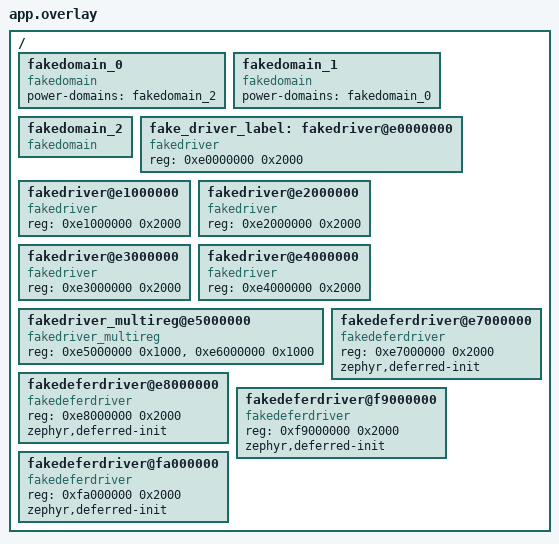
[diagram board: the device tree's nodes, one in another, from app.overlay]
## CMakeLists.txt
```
# SPDX-License-Identifier: Apache-2.0

cmake_minimum_required(VERSION 3.28.0)
find_package(Zephyr REQUIRED HINTS $ENV{ZEPHYR_BASE})
project(device)

FILE(GLOB app_sources src/*.c)
target_sources(app PRIVATE ${app_sources})

# device_get_binding() compares pointers first before doing strcmp().
# However, enabling coverage forces -O0 to disable any compiler
# optimizations. There would be multiple copies of the same string,
# and the code pathing doing pointer comparison would not be tested
# at all. So add this flag to merge string constants such that
# the pointer comparison would be exercised.
zephyr_cc_option_ifdef(CONFIG_COVERAGE -fmerge-constants)
```

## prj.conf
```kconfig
CONFIG_ZTEST=y
CONFIG_TEST_USERSPACE=y
CONFIG_PM_DEVICE=y
CONFIG_PM_DEVICE_RUNTIME=y
CONFIG_APPLICATION_DEFINED_SYSCALL=y
CONFIG_DEVICE_DEINIT_SUPPORT=y
```

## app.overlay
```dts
/*
 * Copyright (c) 2020 Nordic Semiconductor ASA
 * Copyright (c) 2020 Intel Corporation
 *
 * SPDX-License-Identifier: Apache-2.0
 *
 * Application overlay for creating a fake device instance we
 * can use to test DEVICE_MMIO APIs, which get raw data about
 * memory ranges from DTS instances.
 *
 * Names in this file should be chosen in a way that won't conflict
 * with real-world devicetree nodes, to allow these tests to run on
 * (and be extended to test) real hardware.
 */

/ {
	#address-cells = <1>;
	#size-cells = <1>;

	fakedomain_0: fakedomain_0 {
		compatible = "fakedomain";
		power-domains = <&fakedomain_2>;
		#power-domain-cells = <0>;
		status = "okay";
	};

	fakedomain_1: fakedomain_1 {
		compatible = "fakedomain";
		power-domains = <&fakedomain_0>;
		#power-domain-cells = <0>;
		status = "okay";
	};

	fakedomain_2: fakedomain_2 {
		compatible = "fakedomain";
		#power-domain-cells = <0>;
		status = "okay";
	};

	fake_driver_label: fakedriver@e0000000 {
		compatible = "fakedriver";
		reg = <0xe0000000 0x2000>;
		status = "okay";
	};

	fakedriver@e1000000 {
		compatible = "fakedriver";
		reg = <0xe1000000 0x2000>;
		status = "okay";
	};

	fakedriver@e2000000 {
		compatible = "fakedriver";
		reg = <0xe2000000 0x2000>;
		status = "okay";
	};

	fakedriver@e3000000 {
		compatible = "fakedriver";
		reg = <0xe3000000 0x2000>;
		status = "okay";
	};

	fakedriver@e4000000 {
		compatible = "fakedriver";
		reg = <0xe4000000 0x2000>;
		status = "okay";
	};

	fakedriver_multireg@e5000000 {
		compatible = "fakedriver_multireg";
		reg = <0xe5000000 0x1000>,
		      <0xe6000000 0x1000>;
		reg-names = "chip",
			    "dale";
		status = "okay";
	};

	fakedeferdriver@e7000000 {
		compatible = "fakedeferdriver";
		reg = <0xe7000000 0x2000>;
		zephyr,deferred-init;
		status = "okay";
	};

	fakedeferdriver@e8000000 {
		compatible = "fakedeferdriver";
		reg = <0xe8000000 0x2000>;
		zephyr,deferred-init;
		status = "okay";
	};

	fakedeferdriver@f9000000 {
		compatible = "fakedeferdriver";
		reg = <0xf9000000 0x2000>;
		zephyr,deferred-init;
		status = "okay";
	};

	fakedeferdriver@fa000000 {
		compatible = "fakedeferdriver";
		reg = <0xfa000000 0x2000>;
		zephyr,deferred-init;
		status = "okay";
	};
};
```

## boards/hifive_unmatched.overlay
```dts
/*
 * Copyright (c) 2020 Nordic Semiconductor ASA
 * Copyright (c) 2020 Intel Corporation
 *
 * SPDX-License-Identifier: Apache-2.0
 *
 * Application overlay for creating a fake device instance we
 * can use to test DEVICE_MMIO APIs, which get raw data about
 * memory ranges from DTS instances.
 *
 * Names in this file should be chosen in a way that won't conflict
 * with real-world devicetree nodes, to allow these tests to run on
 * (and be extended to test) real hardware.
 */

/ {
	fakedriver@E0000000 {
		compatible = "fakedriver";
		reg = <0x0 0xE0000000 0x0 0x2000>;
		status = "okay";
	};
	fakedriver@E1000000 {
		compatible = "fakedriver";
		reg = <0x0 0xE1000000 0x0 0x2000>;
		status = "okay";
	};
	fakedriver@E2000000 {
		compatible = "fakedriver";
		reg = <0x0 0xE2000000 0x0 0x2000>;
		status = "okay";
	};
	fakedriver@E3000000 {
		compatible = "fakedriver";
		reg = <0x0 0xE3000000 0x0 0x2000>;
		status = "okay";
	};
	fakedriver@E4000000 {
		compatible = "fakedriver";
		reg = <0x0 0xE4000000 0x0 0x2000>;
		status = "okay";
	};

	fakedriver_multireg@E5000000 {
		compatible = "fakedriver_multireg";
		reg = <0x0 0xE5000000 0x0 0x1000>,
		      <0x0 0xE6000000 0x0 0x1000>;
		reg-names = "chip",
			    "dale";
		status = "okay";
	};

	fakedeferdriver@E7000000 {
		compatible = "fakedeferdriver";
		reg = <0x0 0xE7000000 0x0 0x2000>;
		status = "okay";
		zephyr,deferred-init;
	};

	fakedeferdriver@E8000000 {
		compatible = "fakedeferdriver";
		reg = <0x0 0xE8000000 0x0 0x2000>;
		status = "okay";
		zephyr,deferred-init;
	};

	fakedomain_0: fakedomain_0 {
		compatible = "fakedomain";
		status = "okay";
		#power-domain-cells = <0>;
		power-domains = <&fakedomain_2>;
	};

	fakedomain_1: fakedomain_1 {
		compatible = "fakedomain";
		status = "okay";
		#power-domain-cells = <0>;
		power-domains = <&fakedomain_0>;
	};

	fakedomain_2: fakedomain_2 {
		compatible = "fakedomain";
		status = "okay";
		#power-domain-cells = <0>;
	};
};
```

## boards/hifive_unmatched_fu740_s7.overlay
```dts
/*
 * Copyright (c) 2020 Nordic Semiconductor ASA
 * Copyright (c) 2020 Intel Corporation
 *
 * SPDX-License-Identifier: Apache-2.0
 *
 * Application overlay for creating a fake device instance we
 * can use to test DEVICE_MMIO APIs, which get raw data about
 * memory ranges from DTS instances.
 *
 * Names in this file should be chosen in a way that won't conflict
 * with real-world devicetree nodes, to allow these tests to run on
 * (and be extended to test) real hardware.
 */

/ {
	fakedriver@e0000000 {
		compatible = "fakedriver";
		reg = <0x0 0xe0000000 0x0 0x2000>;
		status = "okay";
	};

	fakedriver@e1000000 {
		compatible = "fakedriver";
		reg = <0x0 0xe1000000 0x0 0x2000>;
		status = "okay";
	};

	fakedriver@e2000000 {
		compatible = "fakedriver";
		reg = <0x0 0xe2000000 0x0 0x2000>;
		status = "okay";
	};

	fakedriver@e3000000 {
		compatible = "fakedriver";
		reg = <0x0 0xe3000000 0x0 0x2000>;
		status = "okay";
	};

	fakedriver@e4000000 {
		compatible = "fakedriver";
		reg = <0x0 0xe4000000 0x0 0x2000>;
		status = "okay";
	};

	fakedriver_multireg@e5000000 {
		compatible = "fakedriver_multireg";
		reg = <0x0 0xe5000000 0x0 0x1000>,
		      <0x0 0xe6000000 0x0 0x1000>;
		reg-names = "chip",
			    "dale";
		status = "okay";
	};

	fakedeferdriver@e7000000 {
		compatible = "fakedeferdriver";
		reg = <0x0 0xe7000000 0x0 0x2000>;
		status = "okay";
		zephyr,deferred-init;
	};

	fakedeferdriver@e8000000 {
		compatible = "fakedeferdriver";
		reg = <0x0 0xe8000000 0x0 0x2000>;
		status = "okay";
		zephyr,deferred-init;
	};

	fakedeferdriver@f9000000 {
		compatible = "fakedeferdriver";
		reg = <0x0 0xf9000000 0x0 0x2000>;
		status = "okay";
		zephyr,deferred-init;
	};

	fakedeferdriver@fa000000 {
		compatible = "fakedeferdriver";
		reg = <0x0 0xfa000000 0x0 0x2000>;
		status = "okay";
		zephyr,deferred-init;
	};

	fakedomain_0: fakedomain_0 {
		compatible = "fakedomain";
		status = "okay";
		#power-domain-cells = <0>;
		power-domains = <&fakedomain_2>;
	};

	fakedomain_1: fakedomain_1 {
		compatible = "fakedomain";
		status = "okay";
		#power-domain-cells = <0>;
		power-domains = <&fakedomain_0>;
	};

	fakedomain_2: fakedomain_2 {
		compatible = "fakedomain";
		status = "okay";
		#power-domain-cells = <0>;
	};
};
```

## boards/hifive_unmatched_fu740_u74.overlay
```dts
/*
 * Copyright (c) 2020 Nordic Semiconductor ASA
 * Copyright (c) 2020 Intel Corporation
 *
 * SPDX-License-Identifier: Apache-2.0
 *
 * Application overlay for creating a fake device instance we
 * can use to test DEVICE_MMIO APIs, which get raw data about
 * memory ranges from DTS instances.
 *
 * Names in this file should be chosen in a way that won't conflict
 * with real-world devicetree nodes, to allow these tests to run on
 * (and be extended to test) real hardware.
 */

/ {
	fakedriver@e0000000 {
		compatible = "fakedriver";
		reg = <0x0 0xe0000000 0x0 0x2000>;
		status = "okay";
	};

	fakedriver@e1000000 {
		compatible = "fakedriver";
		reg = <0x0 0xe1000000 0x0 0x2000>;
		status = "okay";
	};

	fakedriver@e2000000 {
		compatible = "fakedriver";
		reg = <0x0 0xe2000000 0x0 0x2000>;
		status = "okay";
	};

	fakedriver@e3000000 {
		compatible = "fakedriver";
		reg = <0x0 0xe3000000 0x0 0x2000>;
		status = "okay";
	};

	fakedriver@e4000000 {
		compatible = "fakedriver";
		reg = <0x0 0xe4000000 0x0 0x2000>;
		status = "okay";
	};

	fakedriver_multireg@e5000000 {
		compatible = "fakedriver_multireg";
		reg = <0x0 0xe5000000 0x0 0x1000>,
		      <0x0 0xe6000000 0x0 0x1000>;
		reg-names = "chip",
			    "dale";
		status = "okay";
	};

	fakedeferdriver@e7000000 {
		compatible = "fakedeferdriver";
		reg = <0x0 0xe7000000 0x0 0x2000>;
		zephyr,deferred-init;
		status = "okay";
	};

	fakedeferdriver@e8000000 {
		compatible = "fakedeferdriver";
		reg = <0x0 0xe8000000 0x0 0x2000>;
		zephyr,deferred-init;
		status = "okay";
	};

	fakedeferdriver@f9000000 {
		compatible = "fakedeferdriver";
		reg = <0x0 0xf9000000 0x0 0x2000>;
		zephyr,deferred-init;
		status = "okay";
	};

	fakedeferdriver@fa000000 {
		compatible = "fakedeferdriver";
		reg = <0x0 0xfa000000 0x0 0x2000>;
		zephyr,deferred-init;
		status = "okay";
	};

	fakedomain_0: fakedomain_0 {
		compatible = "fakedomain";
		#power-domain-cells = <0>;
		power-domains = <&fakedomain_2>;
		status = "okay";
	};

	fakedomain_1: fakedomain_1 {
		compatible = "fakedomain";
		#power-domain-cells = <0>;
		power-domains = <&fakedomain_0>;
		status = "okay";
	};

	fakedomain_2: fakedomain_2 {
		compatible = "fakedomain";
		#power-domain-cells = <0>;
		status = "okay";
	};
};
```

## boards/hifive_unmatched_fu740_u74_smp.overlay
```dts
/*
 * Copyright (c) 2020 Nordic Semiconductor ASA
 * Copyright (c) 2020 Intel Corporation
 *
 * SPDX-License-Identifier: Apache-2.0
 *
 * Application overlay for creating a fake device instance we
 * can use to test DEVICE_MMIO APIs, which get raw data about
 * memory ranges from DTS instances.
 *
 * Names in this file should be chosen in a way that won't conflict
 * with real-world devicetree nodes, to allow these tests to run on
 * (and be extended to test) real hardware.
 */

/ {
	#address-cells = <2>;
	#size-cells = <2>;

	fakedriver@E0000000 {
		compatible = "fakedriver";
		reg = <0x0 0xE0000000 0x0 0x2000>;
		status = "okay";
	};
	fakedriver@E1000000 {
		compatible = "fakedriver";
		reg = <0x0 0xE1000000 0x0 0x2000>;
		status = "okay";
	};
	fakedriver@E2000000 {
		compatible = "fakedriver";
		reg = <0x0 0xE2000000 0x0 0x2000>;
		status = "okay";
	};
	fakedriver@E3000000 {
		compatible = "fakedriver";
		reg = <0x0 0xE3000000 0x0 0x2000>;
		status = "okay";
	};
	fakedriver@E4000000 {
		compatible = "fakedriver";
		reg = <0x0 0xE4000000 0x0 0x2000>;
		status = "okay";
	};

	fakedriver_multireg@E5000000 {
		compatible = "fakedriver_multireg";
		reg = <0x0 0xE5000000 0x0 0x1000>,
		      <0x0 0xE6000000 0x0 0x1000>;
		reg-names = "chip",
			    "dale";
		status = "okay";
	};

	fakedeferdriver@E7000000 {
		compatible = "fakedeferdriver";
		reg = <0x0 0xE7000000 0x0 0x2000>;
		status = "okay";
		zephyr,deferred-init;
	};

	fakedeferdriver@E8000000 {
		compatible = "fakedeferdriver";
		reg = <0x0 0xE8000000 0x0 0x2000>;
		status = "okay";
		zephyr,deferred-init;
	};

	fakedomain_0: fakedomain_0 {
		compatible = "fakedomain";
		status = "okay";
		power-domain = <&fakedomain_2>;
	};

	fakedomain_1: fakedomain_1 {
		compatible = "fakedomain";
		status = "okay";
		power-domain = <&fakedomain_0>;
	};

	fakedomain_2: fakedomain_2 {
		compatible = "fakedomain";
		status = "okay";
	};
};
```

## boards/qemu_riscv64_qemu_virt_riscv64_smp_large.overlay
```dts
/*
 * Copyright (c) 2020 Nordic Semiconductor ASA
 * Copyright (c) 2020 Intel Corporation
 * Copyright (c) Qualcomm Technologies, Inc. and/or its subsidiaries.
 *
 * SPDX-License-Identifier: Apache-2.0
 *
 * Board-specific overlay for qemu_riscv64/qemu_virt_riscv64/smp_large.
 * This board uses #address-cells = <2> at root, so fake device reg values
 * must use two address cells.  The root #address-cells is NOT overridden
 * here (unlike app.overlay) to avoid breaking the ram0 node at 0x100000000.
 */

/ {
	fake_driver_label: fakedriver@e0000000 {
		compatible = "fakedriver";
		reg = <0x0 0xe0000000 0x0 0x2000>;
		status = "okay";
	};

	fakedriver@e1000000 {
		compatible = "fakedriver";
		reg = <0x0 0xe1000000 0x0 0x2000>;
		status = "okay";
	};

	fakedriver@e2000000 {
		compatible = "fakedriver";
		reg = <0x0 0xe2000000 0x0 0x2000>;
		status = "okay";
	};

	fakedriver@e3000000 {
		compatible = "fakedriver";
		reg = <0x0 0xe3000000 0x0 0x2000>;
		status = "okay";
	};

	fakedriver@e4000000 {
		compatible = "fakedriver";
		reg = <0x0 0xe4000000 0x0 0x2000>;
		status = "okay";
	};

	fakedriver_multireg@e5000000 {
		compatible = "fakedriver_multireg";
		reg = <0x0 0xe5000000 0x0 0x1000>,
		      <0x0 0xe6000000 0x0 0x1000>;
		reg-names = "chip",
			    "dale";
		status = "okay";
	};

	fakedeferdriver@e7000000 {
		compatible = "fakedeferdriver";
		reg = <0x0 0xe7000000 0x0 0x2000>;
		status = "okay";
		zephyr,deferred-init;
	};

	fakedeferdriver@e8000000 {
		compatible = "fakedeferdriver";
		reg = <0x0 0xe8000000 0x0 0x2000>;
		status = "okay";
		zephyr,deferred-init;
	};

	fakedeferdriver@f9000000 {
		compatible = "fakedeferdriver";
		reg = <0x0 0xf9000000 0x0 0x2000>;
		status = "okay";
		zephyr,deferred-init;
	};

	fakedomain_0: fakedomain_0 {
		compatible = "fakedomain";
		status = "okay";
		#power-domain-cells = <0>;
		power-domains = <&fakedomain_2>;
	};

	fakedomain_1: fakedomain_1 {
		compatible = "fakedomain";
		status = "okay";
		#power-domain-cells = <0>;
		power-domains = <&fakedomain_0>;
	};

	fakedomain_2: fakedomain_2 {
		compatible = "fakedomain";
		status = "okay";
		#power-domain-cells = <0>;
	};
};
```

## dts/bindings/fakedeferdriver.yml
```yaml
# Copyright (c) 2023 Intel Corporation
# SPDX-License-Identifier: Apache-2.0

description: Properties for fake deferred driver.

compatible: "fakedeferdriver"

include: base.yaml
```

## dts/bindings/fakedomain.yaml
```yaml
# Copyright (c) 2023, CSIRO
# SPDX-License-Identifier: Apache-2.0

description: Properties for fake power domain

compatible: "fakedomain"

include: base.yaml
```

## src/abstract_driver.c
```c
/*
 * Copyright (c) 2020 Intel Corporation
 *
 * SPDX-License-Identifier: Apache-2.0
 */

#include <zephyr/ztest.h>
#include <zephyr/device.h>
#include "abstract_driver.h"

#define MY_DRIVER_A		"my_driver_A"
#define MY_DRIVER_B		"my_driver_B"
#define MY_CHILD_DRIVER		"my_child_driver"
#define MY_GRANDCHILD_DRIVER	"my_grandchild_driver"
#define MY_SIBLING_DRIVER	"my_sibling_driver"

/* define individual driver A */
static int my_driver_A_do_this(const struct device *dev, int foo, int bar)
{
	return foo + bar;
}

static void my_driver_A_do_that(const struct device *dev, unsigned int *baz)
{
	*baz = 1;
}

static DEVICE_API(abstract, my_driver_A_api_funcs) = {
	.do_this = my_driver_A_do_this,
	.do_that = my_driver_A_do_that,
};

int common_driver_init(const struct device *dev)
{
	return 0;
}

/* define individual driver B */
static int my_driver_B_do_this(const struct device *dev, int foo, int bar)
{
	return foo - bar;
}

static void my_driver_B_do_that(const struct device *dev, unsigned int *baz)
{
	*baz = 2;
}

static DEVICE_API(abstract, my_driver_B_api_funcs) = {
	.do_this = my_driver_B_do_this,
	.do_that = my_driver_B_do_that,
};

/* define child driver */
static int child_driver_do_this(const struct device *dev, int foo, int bar)
{
	return foo * bar;
}

static void child_driver_do_that(const struct device *dev, unsigned int *baz)
{
	*baz = 3;
}

static int child_driver_do_these(const struct device *dev)
{
	unsigned int baz;

	/* Make it full-circle and call parent APIs */
	abstract_do_that(dev, &baz);
	return abstract_do_this(dev, (int)baz, (int)baz);
}

static DEVICE_API(abstract_child, child_driver_api_funcs) = {
	.abstract_api = {
		.do_this = child_driver_do_this,
		.do_that = child_driver_do_that,
	},
	.do_these = child_driver_do_these,
};

/* define grandchild driver (extends child, which extends abstract) */
static int grandchild_driver_do_this(const struct device *dev, int foo, int bar)
{
	return foo + bar + 1;
}

static void grandchild_driver_do_that(const struct device *dev, unsigned int *baz)
{
	*baz = 4;
}

static int grandchild_driver_do_these(const struct device *dev)
{
	unsigned int baz;

	abstract_do_that(dev, &baz);
	return abstract_do_this(dev, (int)baz, (int)baz);
}

static int grandchild_driver_do_all(const struct device *dev, int val)
{
	/* Combine all levels: call parent APIs and add own contribution */
	int ret = abstract_child_do_these(dev);

	return ret + val;
}

static DEVICE_API(abstract_grandchild, grandchild_driver_api_funcs) = {
	.abstract_child_api = {
		.abstract_api = {
			.do_this = grandchild_driver_do_this,
			.do_that = grandchild_driver_do_that,
		},
		.do_these = grandchild_driver_do_these,
	},
	.do_all = grandchild_driver_do_all,
};

/* define sibling driver (extends abstract, sibling of child) */
static int sibling_driver_do_this(const struct device *dev, int foo, int bar)
{
	return foo % bar;
}

static void sibling_driver_do_that(const struct device *dev, unsigned int *baz)
{
	*baz = 5;
}

static int sibling_driver_do_other(const struct device *dev, int val)
{
	return val * 10;
}

static DEVICE_API(abstract_sibling, sibling_driver_api_funcs) = {
	.abstract_api = {
		.do_this = sibling_driver_do_this,
		.do_that = sibling_driver_do_that,
	},
	.do_other = sibling_driver_do_other,
};

/**
 * @cond INTERNAL_HIDDEN
 */
DEVICE_DEFINE(my_driver_A, MY_DRIVER_A, &common_driver_init,
		NULL, NULL, NULL,
		POST_KERNEL, CONFIG_KERNEL_INIT_PRIORITY_DEFAULT,
		&my_driver_A_api_funcs);

DEVICE_DEFINE(my_driver_B, MY_DRIVER_B, &common_driver_init,
		NULL, NULL, NULL,
		POST_KERNEL, CONFIG_KERNEL_INIT_PRIORITY_DEFAULT,
		&my_driver_B_api_funcs);

DEVICE_DEFINE(my_child_driver, MY_CHILD_DRIVER, &common_driver_init,
		NULL, NULL, NULL,
		POST_KERNEL, CONFIG_KERNEL_INIT_PRIORITY_DEFAULT,
		&child_driver_api_funcs);

DEVICE_DEFINE(my_grandchild_driver, MY_GRANDCHILD_DRIVER, &common_driver_init,
		NULL, NULL, NULL,
		POST_KERNEL, CONFIG_KERNEL_INIT_PRIORITY_DEFAULT,
		&grandchild_driver_api_funcs);

DEVICE_DEFINE(my_sibling_driver, MY_SIBLING_DRIVER, &common_driver_init,
		NULL, NULL, NULL,
		POST_KERNEL, CONFIG_KERNEL_INIT_PRIORITY_DEFAULT,
		&sibling_driver_api_funcs);
/**
 * @endcond
 */
```

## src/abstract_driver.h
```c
/*
 * Copyright (c) 2020 Intel Corporation
 *
 * SPDX-License-Identifier: Apache-2.0
 */

#ifndef _ABSTRACT_DRIVER_H_
#define _ABSTRACT_DRIVER_H_

#include <zephyr/ztest.h>
#include <zephyr/device.h>
#include <zephyr/sys/check.h>

/* define subsystem common API for drivers */
typedef int (*abstract_do_this_t)(const struct device *dev, int foo, int bar);
typedef void (*abstract_do_that_t)(const struct device *dev, unsigned int *baz);

__subsystem struct abstract_driver_api {
	abstract_do_this_t do_this;
	abstract_do_that_t do_that;
};

__syscall int abstract_do_this(const struct device *dev, int foo, int bar);

static inline int z_impl_abstract_do_this(const struct device *dev, int foo, int bar)
{
	__ASSERT_NO_MSG(DEVICE_API_IS(abstract, dev));

	return DEVICE_API_GET(abstract, dev)->do_this(dev, foo, bar);
}

__syscall void abstract_do_that(const struct device *dev, unsigned int *baz);

static inline void z_impl_abstract_do_that(const struct device *dev, unsigned int *baz)
{
	__ASSERT_NO_MSG(DEVICE_API_IS(abstract, dev));

	DEVICE_API_GET(abstract, dev)->do_that(dev, baz);
}

typedef int (*abstract_child_do_these_t)(const struct device *dev);

__subsystem struct abstract_child_driver_api {
	/* Embed parent API */
	struct abstract_driver_api abstract_api;

	abstract_child_do_these_t do_these;
};

/* Declare relation */
DEVICE_API_EXTENDS(abstract_child, abstract, abstract_api);

static inline int z_impl_abstract_child_do_these(const struct device *dev)
{
	return DEVICE_API_GET(abstract_child, dev)->do_these(dev);
}

__syscall int abstract_child_do_these(const struct device *dev);

/* Grandchild API: extends abstract_child (3-level inheritance) */
typedef int (*abstract_grandchild_do_all_t)(const struct device *dev, int val);

__subsystem struct abstract_grandchild_driver_api {
	/* Embed parent (child) API */
	struct abstract_child_driver_api abstract_child_api;

	abstract_grandchild_do_all_t do_all;
};

DEVICE_API_EXTENDS(abstract_grandchild, abstract_child, abstract_child_api);

static inline int z_impl_abstract_grandchild_do_all(const struct device *dev, int val)
{
	return DEVICE_API_GET(abstract_grandchild, dev)->do_all(dev, val);
}

__syscall int abstract_grandchild_do_all(const struct device *dev, int val);

/* Sibling API: also extends abstract (sibling of abstract_child) */
typedef int (*abstract_sibling_do_other_t)(const struct device *dev, int val);

__subsystem struct abstract_sibling_driver_api {
	/* Embed parent API */
	struct abstract_driver_api abstract_api;

	abstract_sibling_do_other_t do_other;
};

DEVICE_API_EXTENDS(abstract_sibling, abstract, abstract_api);

static inline int z_impl_abstract_sibling_do_other(const struct device *dev, int val)
{
	return DEVICE_API_GET(abstract_sibling, dev)->do_other(dev, val);
}

__syscall int abstract_sibling_do_other(const struct device *dev, int val);

#include <zephyr/syscalls/abstract_driver.h>

#endif /* _ABSTRACT_DRIVER_H_ */
```

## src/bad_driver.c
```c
/*
 * Copyright (c) 2019 Intel Corporation
 *
 * SPDX-License-Identifier: Apache-2.0
 */

#include <zephyr/kernel.h>
#include <zephyr/device.h>


#define BAD_DRIVER_NAME	"bad_driver"

typedef int (*bad_api_configure_t)(const struct device *dev,
				     uint32_t dev_config);


struct bad_driver_api {
	bad_api_configure_t configure;
};

static int bad_configure(const struct device *dev, uint32_t config)
{
	return 0;
}

static const struct bad_driver_api funcs = {
	.configure = bad_configure,
};

int bad_driver_init(const struct device *dev)
{
	return -EINVAL;
}

/**
 * @cond INTERNAL_HIDDEN
 */
DEVICE_DEFINE(bad_driver, BAD_DRIVER_NAME, &bad_driver_init,
		NULL, NULL, NULL, POST_KERNEL,
		CONFIG_KERNEL_INIT_PRIORITY_DEFAULT, &funcs);

/**
 * @endcond
 */
```

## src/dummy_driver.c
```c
/*
 * Copyright (c) 2018 Intel Corporation
 *
 * SPDX-License-Identifier: Apache-2.0
 */

#include <zephyr/kernel.h>
#include <zephyr/device.h>


#define DUMMY_DRIVER_NAME	"dummy_driver"

typedef int (*dummy_api_configure_t)(const struct device *dev,
				     uint32_t dev_config);


struct dummy_driver_api {
	dummy_api_configure_t configure;
};

static int dummy_configure(const struct device *dev, uint32_t config)
{
	return 0;
}

static const struct dummy_driver_api funcs = {
	.configure = dummy_configure,
};

int dummy_init(const struct device *dev)
{
	return 0;
}

/**
 * @cond INTERNAL_HIDDEN
 */
DEVICE_INSTANCE(dummy_driver, dummy_init, NULL, NULL, NULL,
	      POST_KERNEL, &funcs);

/**
 * @endcond
 */
```

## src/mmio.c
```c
/*
 * Copyright (c) 2020 Intel Corporation
 *
 * SPDX-License-Identifier: Apache-2.0
 */

#include <string.h>
#include <zephyr/ztest.h>
#include <zephyr/device.h>

#define DT_DRV_COMPAT	fakedriver

/*
 * Driver with a single MMIO region to manage
 */

struct foo_single_dev_data {
	DEVICE_MMIO_RAM;
	int baz;
};

struct foo_single_dev_data foo0_data;

struct foo_single_config_info {
	DEVICE_MMIO_ROM;
};

const struct foo_single_config_info foo0_config = {
	DEVICE_MMIO_ROM_INIT(DT_DRV_INST(0)),
};

int foo_single_init(const struct device *dev)
{
	DEVICE_MMIO_MAP(dev, K_MEM_CACHE_NONE);

	return 0;
}

/* fake API pointer, we don't use it at all for this suite */
DEVICE_DEFINE(foo0, "foo0", foo_single_init, NULL,
		&foo0_data, &foo0_config,
		POST_KERNEL, CONFIG_KERNEL_INIT_PRIORITY_DEFAULT,
		(void *)0xDEADBEEF);

/**
 * @brief Test DEVICE_MMIO_* macros
 *
 * We show that we can make mapping calls and that the address returned by
 * DEVICE_MMIO_GET() is not NULL, indicating that the kernel mapped
 * stuff somewhere.
 *
 * We also perform some checks depending on configuration:
 * - If MMIO addresses are maintained in RAM, check that the ROM struct
 *   was populated correctly.
 * - If MMIO addresses are maintained in ROM, check that the DTS info,
 *   the ROM region, and the result of DEVICE_MMIO_GET() all
 *   point to the same address. We show that no extra memory is used in
 *   dev_data.
 *
 * @ingroup kernel_device_tests
 */
ZTEST(device, test_mmio_single)
{
	const struct z_device_mmio_rom *rom;
	const struct device *dev = device_get_binding("foo0");
	mm_reg_t regs;

	zassert_not_null(dev, "null foo0");

	regs = DEVICE_MMIO_GET(dev);
	rom = DEVICE_MMIO_ROM_PTR(dev);

	/* A sign that something didn't get initialized, shouldn't ever
	 * be 0
	 */
	zassert_not_equal(regs, 0, "NULL regs");

#ifdef DEVICE_MMIO_IS_IN_RAM
	/* The config info should just contain the addr/size from DTS.
	 * The best we can check with 'regs' is that it's nonzero, as if
	 * an MMU is enabled, the kernel chooses the virtual address to
	 * place it at. We don't otherwise look at `regs`; other tests will
	 * prove that k_map() actually works.
	 */
	zassert_equal(rom->phys_addr, DT_INST_REG_ADDR(0), "bad phys_addr");
	zassert_equal(rom->size, DT_INST_REG_SIZE(0), "bad size");
#else
	/* Config info contains base address, which should be the base
	 * address from DTS, and regs should have the same value.
	 * In this configuration dev_data has nothing mmio-related in it
	 */
	zassert_equal(rom->addr, DT_INST_REG_ADDR(0), "bad addr");
	zassert_equal(regs, rom->addr, "bad regs");
	/* Just the baz member */
	zassert_equal(sizeof(struct foo_single_dev_data), sizeof(int),
		      "too big foo_single_dev_data");
#endif
}

/*
 * Driver with multiple MMIO regions to manage
 */

struct foo_mult_dev_data {
	int baz;

	DEVICE_MMIO_NAMED_RAM(corge);
	DEVICE_MMIO_NAMED_RAM(grault);
};

struct foo_mult_dev_data foo12_data;

struct foo_mult_config_info {
	DEVICE_MMIO_NAMED_ROM(corge);
	DEVICE_MMIO_NAMED_ROM(grault);
};

const struct foo_mult_config_info foo12_config = {
	DEVICE_MMIO_NAMED_ROM_INIT(corge, DT_DRV_INST(1)),
	DEVICE_MMIO_NAMED_ROM_INIT(grault, DT_DRV_INST(2))
};

#define DEV_DATA(dev)	((struct foo_mult_dev_data *)((dev)->data))
#define DEV_CFG(dev)	((struct foo_mult_config_info *)((dev)->config))

int foo_mult_init(const struct device *dev)
{
	DEVICE_MMIO_NAMED_MAP(dev, corge, K_MEM_CACHE_NONE);
	DEVICE_MMIO_NAMED_MAP(dev, grault, K_MEM_CACHE_NONE);

	return 0;
}

DEVICE_DEFINE(foo12, "foo12", foo_mult_init, NULL,
		&foo12_data, &foo12_config,
		POST_KERNEL, CONFIG_KERNEL_INIT_PRIORITY_DEFAULT,
		(void *)0xDEADBEEF);

/**
 * @brief Test DEVICE_MMIO_NAMED_* macros
 *
 * We show that we can make mapping calls and that the address returned by
 * DEVICE_MMIO_NAMED_GET() is not NULL, indicating that the kernel mapped
 * stuff somewhere.
 *
 * We show that this works for a device instance that has two named regions,
 * 'corge' and 'grault' that respectively come from DTS instances 1 and 2.
 *
 * We also perform some checks depending on configuration:
 * - If MMIO addresses are maintained in RAM, check that the ROM struct
 *   was populated correctly.
 * - If MMIO addresses are maintained in ROM, check that the DTS info,
 *   the ROM region, and the result of DEVICE_MMIO_NAMED_GET() all
 *   point to the same address. We show that no extra memory is used in
 *   dev_data.
 *
 * @ingroup kernel_device_tests
 */
ZTEST(device, test_mmio_multiple)
{
	/* See comments for test_mmio_single */
	const struct device *dev = device_get_binding("foo12");
	mm_reg_t regs_corge, regs_grault;
	const struct z_device_mmio_rom *rom_corge, *rom_grault;

	zassert_not_null(dev, "null foo12");

	regs_corge = DEVICE_MMIO_NAMED_GET(dev, corge);
	regs_grault = DEVICE_MMIO_NAMED_GET(dev, grault);
	rom_corge = DEVICE_MMIO_NAMED_ROM_PTR(dev, corge);
	rom_grault = DEVICE_MMIO_NAMED_ROM_PTR(dev, grault);

	zassert_not_equal(regs_corge, 0, "bad regs_corge");
	zassert_not_equal(regs_grault, 0, "bad regs_grault");

#ifdef DEVICE_MMIO_IS_IN_RAM
	zassert_equal(rom_corge->phys_addr, DT_INST_REG_ADDR(1),
		      "bad phys_addr (corge)");
	zassert_equal(rom_corge->size, DT_INST_REG_SIZE(1),
		      "bad size (corge)");
	zassert_equal(rom_grault->phys_addr, DT_INST_REG_ADDR(2),
		      "bad phys_addr (grault)");
	zassert_equal(rom_grault->size, DT_INST_REG_SIZE(2),
		      "bad size (grault)");
#else
	zassert_equal(rom_corge->addr, DT_INST_REG_ADDR(1),
		      "bad addr (corge)");
	zassert_equal(regs_corge, rom_corge->addr, "bad regs (corge)");
	zassert_equal(rom_grault->addr, DT_INST_REG_ADDR(2),
		      "bad addr (grault)");
	zassert_equal(regs_grault, rom_grault->addr, "bad regs (grault)");
	zassert_equal(sizeof(struct foo_mult_dev_data), sizeof(int),
		      "too big foo_mult_dev_data");
#endif
}

/*
 * RAM buffer standing in for an MMIO region, so that the register access
 * helpers can be exercised on any platform. 64-bit aligned for the 64-bit
 * accessors.
 *
 * sys_read64()/sys_write64() are only guaranteed on 64-bit targets, so the
 * 64-bit helpers are only exercised there.
 */
static uint64_t fake_regs[4];

#define FAKE_REG8	1U
#define FAKE_REG16	2U
#define FAKE_REG32	4U
#define FAKE_REG64	8U
#define FAKE_REG_BITS	16U

static void check_fake_regs(uint8_t *regs)
{
	zassert_equal(regs[FAKE_REG8], 0xA5, "bad 8-bit write");
	zassert_equal(*(uint16_t *)&regs[FAKE_REG16], 0x1234, "bad 16-bit write");
	zassert_equal(*(uint32_t *)&regs[FAKE_REG32], 0xDEADBEEF, "bad 32-bit write");
#ifdef CONFIG_64BIT
	zassert_equal(*(uint64_t *)&regs[FAKE_REG64], 0xFEDCBA9876543210ULL,
		      "bad 64-bit write");
#endif
}

/**
 * @brief Test DEVICE_MMIO_* register access macros
 *
 * A device object whose MMIO storage points at a RAM buffer is built at
 * runtime, then each accessor is checked against the buffer contents.
 *
 * @ingroup kernel_device_tests
 */
ZTEST(device, test_mmio_single_access)
{
	uint8_t *regs = (uint8_t *)fake_regs;
	uint32_t *bits = (uint32_t *)&regs[FAKE_REG_BITS];
#ifdef DEVICE_MMIO_IS_IN_RAM
	mm_reg_t mmio_ram = (mm_reg_t)fake_regs;
	struct device fake = { .data = &mmio_ram };
#else
	struct z_device_mmio_rom mmio_rom = { .addr = (mm_reg_t)fake_regs };
	struct device fake = { .config = &mmio_rom };
#endif
	const struct device *dev = &fake;

	memset(fake_regs, 0, sizeof(fake_regs));

	DEVICE_MMIO_WRITE8(dev, FAKE_REG8, 0xA5);
	DEVICE_MMIO_WRITE16(dev, FAKE_REG16, 0x1234);
	DEVICE_MMIO_WRITE32(dev, FAKE_REG32, 0xDEADBEEF);
#ifdef CONFIG_64BIT
	DEVICE_MMIO_WRITE64(dev, FAKE_REG64, 0xFEDCBA9876543210ULL);
#endif
	check_fake_regs(regs);

	zassert_equal(DEVICE_MMIO_READ8(dev, FAKE_REG8), 0xA5, "bad 8-bit read");
	zassert_equal(DEVICE_MMIO_READ16(dev, FAKE_REG16), 0x1234, "bad 16-bit read");
	zassert_equal(DEVICE_MMIO_READ32(dev, FAKE_REG32), 0xDEADBEEF, "bad 32-bit read");
#ifdef CONFIG_64BIT
	zassert_equal(DEVICE_MMIO_READ64(dev, FAKE_REG64), 0xFEDCBA9876543210ULL,
		      "bad 64-bit read");
#endif

	DEVICE_MMIO_SET_BIT(dev, FAKE_REG_BITS, 3);
	zassert_equal(*bits, BIT(3), "bad set_bit");
	zassert_not_equal(DEVICE_MMIO_TEST_BIT(dev, FAKE_REG_BITS, 3), 0, "bad test_bit");
	zassert_equal(DEVICE_MMIO_TEST_BIT(dev, FAKE_REG_BITS, 4), 0, "bad test_bit");
	DEVICE_MMIO_CLEAR_BIT(dev, FAKE_REG_BITS, 3);
	zassert_equal(*bits, 0, "bad clear_bit");

	zassert_equal(DEVICE_MMIO_TEST_AND_SET_BIT(dev, FAKE_REG_BITS, 5), 0,
		      "bad test_and_set_bit");
	zassert_equal(*bits, BIT(5), "bad test_and_set_bit");
	zassert_not_equal(DEVICE_MMIO_TEST_AND_CLEAR_BIT(dev, FAKE_REG_BITS, 5), 0,
			  "bad test_and_clear_bit");
	zassert_equal(*bits, 0, "bad test_and_clear_bit");

	DEVICE_MMIO_SET_BITS(dev, FAKE_REG_BITS, 0xF0F0);
	zassert_equal(*bits, 0xF0F0, "bad set_bits");
	DEVICE_MMIO_CLEAR_BITS(dev, FAKE_REG_BITS, 0x00F0);
	zassert_equal(*bits, 0xF000, "bad clear_bits");
}

/**
 * @brief Test DEVICE_MMIO_NAMED_* register access macros
 *
 * Same as test_mmio_single_access, for the named region 'corge'.
 *
 * @ingroup kernel_device_tests
 */
ZTEST(device, test_mmio_named_access)
{
	uint8_t *regs = (uint8_t *)fake_regs;
	uint32_t *bits = (uint32_t *)&regs[FAKE_REG_BITS];
#ifdef DEVICE_MMIO_IS_IN_RAM
	struct foo_mult_dev_data data = { .corge = (mm_reg_t)fake_regs };
	struct device fake = { .data = &data };
#else
	struct foo_mult_config_info config = { .corge = { .addr = (mm_reg_t)fake_regs } };
	struct device fake = { .config = &config };
#endif
	const struct device *dev = &fake;

	memset(fake_regs, 0, sizeof(fake_regs));

	DEVICE_MMIO_NAMED_WRITE8(dev, corge, FAKE_REG8, 0xA5);
	DEVICE_MMIO_NAMED_WRITE16(dev, corge, FAKE_REG16, 0x1234);
	DEVICE_MMIO_NAMED_WRITE32(dev, corge, FAKE_REG32, 0xDEADBEEF);
#ifdef CONFIG_64BIT
	DEVICE_MMIO_NAMED_WRITE64(dev, corge, FAKE_REG64, 0xFEDCBA9876543210ULL);
#endif
	check_fake_regs(regs);

	zassert_equal(DEVICE_MMIO_NAMED_READ8(dev, corge, FAKE_REG8), 0xA5, "bad 8-bit read");
	zassert_equal(DEVICE_MMIO_NAMED_READ16(dev, corge, FAKE_REG16), 0x1234,
		      "bad 16-bit read");
	zassert_equal(DEVICE_MMIO_NAMED_READ32(dev, corge, FAKE_REG32), 0xDEADBEEF,
		      "bad 32-bit read");
#ifdef CONFIG_64BIT
	zassert_equal(DEVICE_MMIO_NAMED_READ64(dev, corge, FAKE_REG64), 0xFEDCBA9876543210ULL,
		      "bad 64-bit read");
#endif

	DEVICE_MMIO_NAMED_SET_BIT(dev, corge, FAKE_REG_BITS, 3);
	zassert_equal(*bits, BIT(3), "bad set_bit");
	zassert_not_equal(DEVICE_MMIO_NAMED_TEST_BIT(dev, corge, FAKE_REG_BITS, 3), 0,
			  "bad test_bit");
	zassert_equal(DEVICE_MMIO_NAMED_TEST_BIT(dev, corge, FAKE_REG_BITS, 4), 0,
		      "bad test_bit");
	DEVICE_MMIO_NAMED_CLEAR_BIT(dev, corge, FAKE_REG_BITS, 3);
	zassert_equal(*bits, 0, "bad clear_bit");

	zassert_equal(DEVICE_MMIO_NAMED_TEST_AND_SET_BIT(dev, corge, FAKE_REG_BITS, 5), 0,
		      "bad test_and_set_bit");
	zassert_equal(*bits, BIT(5), "bad test_and_set_bit");
	zassert_not_equal(DEVICE_MMIO_NAMED_TEST_AND_CLEAR_BIT(dev, corge, FAKE_REG_BITS, 5), 0,
			  "bad test_and_clear_bit");
	zassert_equal(*bits, 0, "bad test_and_clear_bit");

	DEVICE_MMIO_NAMED_SET_BITS(dev, corge, FAKE_REG_BITS, 0xF0F0);
	zassert_equal(*bits, 0xF0F0, "bad set_bits");
	DEVICE_MMIO_NAMED_CLEAR_BITS(dev, corge, FAKE_REG_BITS, 0x00F0);
	zassert_equal(*bits, 0xF000, "bad clear_bits");
}

/*
 * Not using driver model, toplevel definition
 */
DEVICE_MMIO_TOPLEVEL(foo3, DT_DRV_INST(3));
DEVICE_MMIO_TOPLEVEL_STATIC(foo4, DT_DRV_INST(4));

/**
 * @brief Test DEVICE_MMIO_TOPLEVEL_* macros
 *
 * We show that we can make mapping calls and that the address returned by
 * DEVICE_MMIO_TOPLEVEL_GET() is not NULL, indicating that the kernel mapped
 * stuff somewhere.
 *
 * We do this for two different MMIO toplevel instances; one declared
 * statically and one not.
 *
 * We also perform some checks depending on configuration:
 * - If MMIO addresses are maintained in RAM, check that the ROM struct
 *   was populated correctly.
 * - If MMIO addresses are maintained in ROM, check that the DTS info,
 *   the ROM region, and the result of DEVICE_MMIO_TOPLEVEL_GET() all
 *   point to the same address
 *
 * @ingroup kernel_device_tests
 */
ZTEST(device, test_mmio_toplevel)
{
	mm_reg_t regs_foo3, regs_foo4;
	const struct z_device_mmio_rom *rom_foo3, *rom_foo4;

	DEVICE_MMIO_TOPLEVEL_MAP(foo3, K_MEM_CACHE_NONE);
	DEVICE_MMIO_TOPLEVEL_MAP(foo4, K_MEM_CACHE_NONE);

	regs_foo3 = DEVICE_MMIO_TOPLEVEL_GET(foo3);
	regs_foo4 = DEVICE_MMIO_TOPLEVEL_GET(foo4);
	rom_foo3 = DEVICE_MMIO_TOPLEVEL_ROM_PTR(foo3);
	rom_foo4 = DEVICE_MMIO_TOPLEVEL_ROM_PTR(foo4);

	zassert_not_equal(regs_foo3, 0, "bad regs_corge");
	zassert_not_equal(regs_foo4, 0, "bad regs_grault");

#ifdef DEVICE_MMIO_IS_IN_RAM
	zassert_equal(rom_foo3->phys_addr, DT_INST_REG_ADDR(3),
		      "bad phys_addr (foo3)");
	zassert_equal(rom_foo3->size, DT_INST_REG_SIZE(3),
		      "bad size (foo3)");
	zassert_equal(rom_foo4->phys_addr, DT_INST_REG_ADDR(4),
		      "bad phys_addr (foo4)");
	zassert_equal(rom_foo4->size, DT_INST_REG_SIZE(4),
		      "bad size (foo4)");
#else
	zassert_equal(rom_foo3->addr, DT_INST_REG_ADDR(3),
		      "bad addr (foo3)");
	zassert_equal(regs_foo3, rom_foo3->addr, "bad regs (foo3)");
	zassert_equal(rom_foo4->addr, DT_INST_REG_ADDR(4),
		      "bad addr (foo4)");
	zassert_equal(regs_foo4, rom_foo4->addr, "bad regs (foo4)");
#endif
}

/**
 * @brief Test DEVICE_MMIO_TOPLEVEL_* register access macros
 *
 * Same as test_mmio_single_access, for the toplevel region 'foo3'. The
 * toplevel address can only be redirected to the RAM buffer when MMIO
 * addresses are maintained in RAM, so the test is skipped otherwise.
 *
 * @ingroup kernel_device_tests
 */
ZTEST(device, test_mmio_toplevel_access)
{
#ifdef DEVICE_MMIO_IS_IN_RAM
	uint8_t *regs = (uint8_t *)fake_regs;
	uint32_t *bits = (uint32_t *)&regs[FAKE_REG_BITS];

	*DEVICE_MMIO_TOPLEVEL_RAM_PTR(foo3) = (mm_reg_t)fake_regs;
	memset(fake_regs, 0, sizeof(fake_regs));

	DEVICE_MMIO_TOPLEVEL_WRITE8(foo3, FAKE_REG8, 0xA5);
	DEVICE_MMIO_TOPLEVEL_WRITE16(foo3, FAKE_REG16, 0x1234);
	DEVICE_MMIO_TOPLEVEL_WRITE32(foo3, FAKE_REG32, 0xDEADBEEF);
#ifdef CONFIG_64BIT
	DEVICE_MMIO_TOPLEVEL_WRITE64(foo3, FAKE_REG64, 0xFEDCBA9876543210ULL);
#endif
	check_fake_regs(regs);

	zassert_equal(DEVICE_MMIO_TOPLEVEL_READ8(foo3, FAKE_REG8), 0xA5, "bad 8-bit read");
	zassert_equal(DEVICE_MMIO_TOPLEVEL_READ16(foo3, FAKE_REG16), 0x1234,
		      "bad 16-bit read");
	zassert_equal(DEVICE_MMIO_TOPLEVEL_READ32(foo3, FAKE_REG32), 0xDEADBEEF,
		      "bad 32-bit read");
#ifdef CONFIG_64BIT
	zassert_equal(DEVICE_MMIO_TOPLEVEL_READ64(foo3, FAKE_REG64), 0xFEDCBA9876543210ULL,
		      "bad 64-bit read");
#endif

	DEVICE_MMIO_TOPLEVEL_SET_BIT(foo3, FAKE_REG_BITS, 3);
	zassert_equal(*bits, BIT(3), "bad set_bit");
	zassert_not_equal(DEVICE_MMIO_TOPLEVEL_TEST_BIT(foo3, FAKE_REG_BITS, 3), 0,
			  "bad test_bit");
	zassert_equal(DEVICE_MMIO_TOPLEVEL_TEST_BIT(foo3, FAKE_REG_BITS, 4), 0, "bad test_bit");
	DEVICE_MMIO_TOPLEVEL_CLEAR_BIT(foo3, FAKE_REG_BITS, 3);
	zassert_equal(*bits, 0, "bad clear_bit");

	zassert_equal(DEVICE_MMIO_TOPLEVEL_TEST_AND_SET_BIT(foo3, FAKE_REG_BITS, 5), 0,
		      "bad test_and_set_bit");
	zassert_equal(*bits, BIT(5), "bad test_and_set_bit");
	zassert_not_equal(DEVICE_MMIO_TOPLEVEL_TEST_AND_CLEAR_BIT(foo3, FAKE_REG_BITS, 5), 0,
			  "bad test_and_clear_bit");
	zassert_equal(*bits, 0, "bad test_and_clear_bit");

	DEVICE_MMIO_TOPLEVEL_SET_BITS(foo3, FAKE_REG_BITS, 0xF0F0);
	zassert_equal(*bits, 0xF0F0, "bad set_bits");
	DEVICE_MMIO_TOPLEVEL_CLEAR_BITS(foo3, FAKE_REG_BITS, 0x00F0);
	zassert_equal(*bits, 0xF000, "bad clear_bits");
#else
	ztest_test_skip();
#endif
}

/**
 * @brief device_map() test
 *
 * Show that device_map() populates a memory address. We don't do anything else;
 * tests for k_map() will prove that virtual memory mapping actually works.
 */
ZTEST(device, test_mmio_device_map)
{
#ifdef DEVICE_MMIO_IS_IN_RAM
	mm_reg_t regs = 0;

	device_map(&regs, 0xF0000000, 0x1000, K_MEM_CACHE_NONE);

	zassert_not_equal(regs, 0, "bad regs");

	device_unmap(regs, 0x1000);
#else
	ztest_test_skip();
#endif
}
```

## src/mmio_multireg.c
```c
/*
 * Copyright (c) 2020 Intel Corporation
 * Copyright (c) 2022 Carlo Caione <ccaione@baylibre.com>
 *
 * SPDX-License-Identifier: Apache-2.0
 */

#include <zephyr/ztest.h>
#include <zephyr/device.h>

#define DT_DRV_COMPAT	fakedriver_multireg

/*
 * Driver with multiple MMIO regions to manage defined into DT
 */

struct foo_multireg_dev_data {
	int baz;

	DEVICE_MMIO_NAMED_RAM(chip);
	DEVICE_MMIO_NAMED_RAM(dale);
};

struct foo_multireg_dev_data foo_multireg_data;

struct foo_multireg_config_info {
	DEVICE_MMIO_NAMED_ROM(chip);
	DEVICE_MMIO_NAMED_ROM(dale);
};

const struct foo_multireg_config_info foo_multireg_config = {
	DEVICE_MMIO_NAMED_ROM_INIT_BY_NAME(chip, DT_DRV_INST(0)),
	DEVICE_MMIO_NAMED_ROM_INIT_BY_NAME(dale, DT_DRV_INST(0))
};

#define DEV_DATA(dev)	((struct foo_multireg_dev_data *)((dev)->data))
#define DEV_CFG(dev)	((struct foo_multireg_config_info *)((dev)->config))

int foo_multireg_init(const struct device *dev)
{
	DEVICE_MMIO_NAMED_MAP(dev, chip, K_MEM_CACHE_NONE);
	DEVICE_MMIO_NAMED_MAP(dev, dale, K_MEM_CACHE_NONE);

	return 0;
}

DEVICE_DEFINE(foo_multireg, "foo_multireg", foo_multireg_init, NULL,
		&foo_multireg_data, &foo_multireg_config,
		POST_KERNEL, CONFIG_KERNEL_INIT_PRIORITY_DEFAULT,
		(void *)0xDEADBEEF);
/**
 * @brief Test DEVICE_MMIO_NAMED_* macros
 *
 * This is the same as the test_mmio_multiple test but in this test the
 * memory regions are created by the named DT property 'reg'.
 *
 * @see test_mmio_multiple
 *
 * @ingroup kernel_device_tests
 */
ZTEST(device, test_mmio_multireg)
{
	const struct device *dev = device_get_binding("foo_multireg");
	mm_reg_t regs_chip, regs_dale;
	const struct z_device_mmio_rom *rom_chip, *rom_dale;

	zassert_not_null(dev, "null foo_multireg");

	regs_chip = DEVICE_MMIO_NAMED_GET(dev, chip);
	regs_dale = DEVICE_MMIO_NAMED_GET(dev, dale);
	rom_chip = DEVICE_MMIO_NAMED_ROM_PTR(dev, chip);
	rom_dale = DEVICE_MMIO_NAMED_ROM_PTR(dev, dale);

	zassert_not_equal(regs_chip, 0, "bad regs_chip");
	zassert_not_equal(regs_dale, 0, "bad regs_dale");

#ifdef DEVICE_MMIO_IS_IN_RAM
	zassert_equal(rom_chip->phys_addr, DT_INST_REG_ADDR_BY_NAME(0, chip),
		      "bad phys_addr (chip)");
	zassert_equal(rom_chip->size, DT_INST_REG_SIZE_BY_NAME(0, chip),
		      "bad size (chip)");
	zassert_equal(rom_dale->phys_addr, DT_INST_REG_ADDR_BY_NAME(0, dale),
		      "bad phys_addr (dale)");
	zassert_equal(rom_dale->size, DT_INST_REG_SIZE_BY_NAME(0, dale),
		      "bad size (dale)");
#else
	zassert_equal(rom_chip->addr, DT_INST_REG_ADDR_BY_NAME(0, chip),
		      "bad addr (chip)");
	zassert_equal(regs_chip, rom_chip->addr, "bad regs (chip)");
	zassert_equal(rom_dale->addr, DT_INST_REG_ADDR_BY_NAME(0, dale),
		      "bad addr (dale)");
	zassert_equal(regs_dale, rom_dale->addr, "bad regs (dale)");
	zassert_equal(sizeof(struct foo_multireg_dev_data), sizeof(int),
		      "too big foo_multireg_dev_data");
#endif
}
```

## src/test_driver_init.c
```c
/*
 * Copyright (c) 2020 Intel Corporation
 *
 * SPDX-License-Identifier: Apache-2.0
 */

#include <zephyr/kernel.h>
#include <zephyr/device.h>
#include <zephyr/init.h>
#include <zephyr/ztest.h>
#include <zephyr/linker/sections.h>


/**
 * @brief Test cases to device driver initialization
 *
 */

#define MY_DRIVER_LV_1    "my_driver_level_1"
#define MY_DRIVER_LV_2    "my_driver_level_2"
#define MY_DRIVER_LV_3    "my_driver_level_3"
#define MY_DRIVER_PRI_1    "my_driver_priority_1"
#define MY_DRIVER_PRI_2    "my_driver_priority_2"
#define MY_DRIVER_PRI_3    "my_driver_priority_3"
#define MY_DRIVER_PRI_4    "my_driver_priority_4"

#define LEVEL_PRE_KERNEL_1	1
#define LEVEL_PRE_KERNEL_2	2
#define LEVEL_POST_KERNEL	3

#define PRIORITY_1	1
#define PRIORITY_2	2
#define PRIORITY_3	3
#define PRIORITY_4	4


/* this is for storing sequence during initialization */
int init_level_sequence[3] = {0};
int init_priority_sequence[4] = {0};
int init_sub_priority_sequence[3] = {0};
unsigned int seq_level_cnt;
unsigned int seq_priority_cnt;
unsigned int seq_sub_priority_cnt;

/* define driver type 1: for testing initialize levels and priorities */
typedef int (*my_api_configure_t)(const struct device *dev, int dev_config);

struct my_driver_api {
	my_api_configure_t configure;
};

static int my_configure(const struct device *dev, int config)
{
	return 0;
}

static const struct my_driver_api funcs_my_drivers = {
	.configure = my_configure,
};

/* driver init function of testing level */
static int my_driver_lv_1_init(const struct device *dev)
{
	init_level_sequence[seq_level_cnt] = LEVEL_PRE_KERNEL_1;
	seq_level_cnt++;

	return 0;
}

static int my_driver_lv_2_init(const struct device *dev)
{
	init_level_sequence[seq_level_cnt] = LEVEL_PRE_KERNEL_2;
	seq_level_cnt++;

	return 0;
}

static int my_driver_lv_3_init(const struct device *dev)
{
	init_level_sequence[seq_level_cnt] = LEVEL_POST_KERNEL;
	seq_level_cnt++;

	return 0;
}

/* driver init function of testing priority */
static int my_driver_pri_1_init(const struct device *dev)
{
	init_priority_sequence[seq_priority_cnt] = PRIORITY_1;
	seq_priority_cnt++;

	return 0;
}

static int my_driver_pri_2_init(const struct device *dev)
{
	init_priority_sequence[seq_priority_cnt] = PRIORITY_2;
	seq_priority_cnt++;

	return 0;
}

static int my_driver_pri_3_init(const struct device *dev)
{
	init_priority_sequence[seq_priority_cnt] = PRIORITY_3;
	seq_priority_cnt++;

	return 0;
}

static int my_driver_pri_4_init(const struct device *dev)
{
	init_priority_sequence[seq_priority_cnt] = PRIORITY_4;
	seq_priority_cnt++;

	return 0;
}

/* driver init function of testing sub_priority */
static int my_driver_sub_pri_0_init(const struct device *dev)
{
	init_sub_priority_sequence[0] = seq_sub_priority_cnt++;

	return 0;
}

static int my_driver_sub_pri_1_init(const struct device *dev)
{
	init_sub_priority_sequence[1] = seq_sub_priority_cnt++;

	return 0;
}

static int my_driver_sub_pri_2_init(const struct device *dev)
{
	init_sub_priority_sequence[2] = seq_sub_priority_cnt++;

	return 0;
}

/**
 * @brief Test providing control device driver initialization order
 *
 * @details Test that kernel shall provide control over device driver
 * initialization order, using initialization level and priority for each
 * instance. We use DEVICE_DEFINE to define device instances and set
 * it's level and priority here, then we run check function later after
 * all of this instance finish their initialization.
 *
 * @ingroup kernel_device_tests
 */
DEVICE_DEFINE(my_driver_level_1, MY_DRIVER_LV_1, &my_driver_lv_1_init,
		NULL, NULL, NULL, PRE_KERNEL_1,
		CONFIG_KERNEL_INIT_PRIORITY_DEFAULT, &funcs_my_drivers);

DEVICE_DEFINE(my_driver_level_2, MY_DRIVER_LV_2, &my_driver_lv_2_init,
		NULL, NULL, NULL, PRE_KERNEL_2,
		CONFIG_KERNEL_INIT_PRIORITY_DEFAULT, &funcs_my_drivers);

DEVICE_DEFINE(my_driver_level_3, MY_DRIVER_LV_3, &my_driver_lv_3_init,
		NULL, NULL, NULL, POST_KERNEL,
		CONFIG_KERNEL_INIT_PRIORITY_DEFAULT, &funcs_my_drivers);

/* We use priority value of 20 to create a possible sorting conflict with
 * priority value of 2.  So if the linker sorting isn't working correctly
 * we'll find out.
 */
DEVICE_DEFINE(my_driver_priority_4, MY_DRIVER_PRI_4,
		&my_driver_pri_4_init, NULL, NULL, NULL, POST_KERNEL, 20,
		&funcs_my_drivers);

DEVICE_DEFINE(my_driver_priority_1, MY_DRIVER_PRI_1,
		&my_driver_pri_1_init, NULL, NULL, NULL, POST_KERNEL, 1,
		&funcs_my_drivers);

DEVICE_DEFINE(my_driver_priority_2, MY_DRIVER_PRI_2,
		&my_driver_pri_2_init, NULL, NULL, NULL, POST_KERNEL, 2,
		&funcs_my_drivers);

DEVICE_DEFINE(my_driver_priority_3, MY_DRIVER_PRI_3,
		&my_driver_pri_3_init, NULL, NULL, NULL, POST_KERNEL, 3,
		&funcs_my_drivers);

/* Create several devices at the same init priority that depend on each
 * other in devicetree so that we can validate linker sorting.
 */
DEVICE_DT_DEFINE(DT_NODELABEL(fakedomain_0), my_driver_sub_pri_0_init,
		NULL, NULL, NULL, POST_KERNEL, 33, NULL);
DEVICE_DT_DEFINE(DT_NODELABEL(fakedomain_1), my_driver_sub_pri_1_init,
		NULL, NULL, NULL, POST_KERNEL, 33, NULL);
DEVICE_DT_DEFINE(DT_NODELABEL(fakedomain_2), my_driver_sub_pri_2_init,
		NULL, NULL, NULL, POST_KERNEL, 33, NULL);
```
